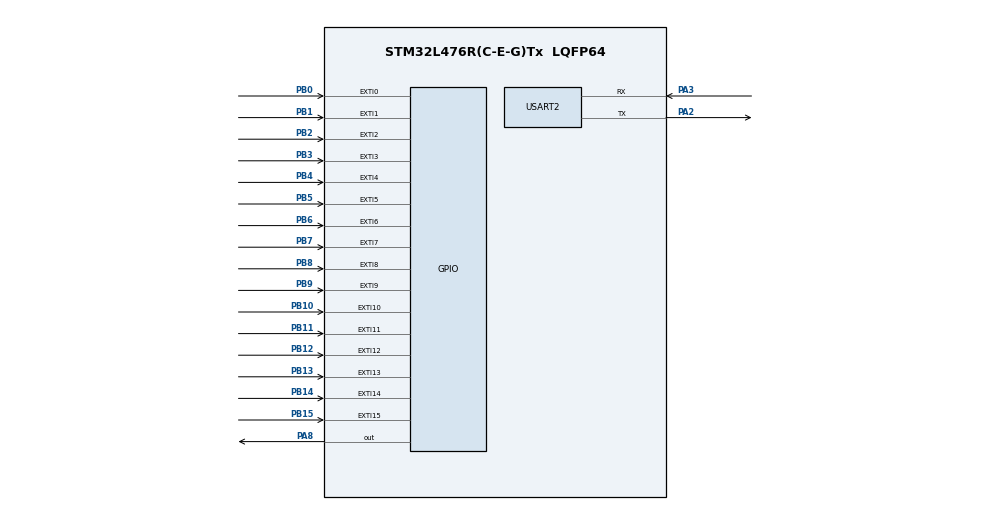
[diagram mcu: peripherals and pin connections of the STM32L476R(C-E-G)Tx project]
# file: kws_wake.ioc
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Dma.Request0=USART2_TX
Dma.USART2_TX.0.Direction=DMA_MEMORY_TO_PERIPH
Dma.USART2_TX.0.Instance=DMA1_Channel7
Dma.USART2_TX.0.MemDataAlignment=DMA_MDATAALIGN_BYTE
Dma.USART2_TX.0.MemInc=DMA_MINC_ENABLE
Dma.USART2_TX.0.Mode=DMA_NORMAL
Dma.USART2_TX.0.PeriphDataAlignment=DMA_PDATAALIGN_BYTE
Dma.USART2_TX.0.PeriphInc=DMA_PINC_DISABLE
Dma.USART2_TX.0.Priority=DMA_PRIORITY_LOW
Mcu.Family=STM32L4
Mcu.Name=STM32L476R(C-E-G)Tx
Mcu.Package=LQFP64
NVIC.DMA1_Channel7_IRQn=true\:0\:0\:false\:false\:true\:false\:true\:true
NVIC.LPTIM1_IRQn=true\:0\:0\:false\:false\:true\:true\:true\:true
NVIC.PriorityGroup=NVIC_PRIORITYGROUP_4
NVIC.USART2_IRQn=true\:0\:0\:false\:false\:true\:false\:true\:true
PA13\ (JTMS-SWDIO).Mode=Serial_Wire
PA13\ (JTMS-SWDIO).Signal=SYS_JTMS-SWDIO
PA14\ (JTCK-SWCLK).Mode=Serial_Wire
PA14\ (JTCK-SWCLK).Signal=SYS_JTCK-SWCLK
PA2.Mode=Asynchronous
PA2.Signal=USART2_TX
PA3.Mode=Asynchronous
PA3.Signal=USART2_RX
PA8.Signal=GPIO_Output
PB0.Signal=GPXTI0
PB1.Signal=GPXTI1
PB10.Signal=GPXTI10
PB11.Signal=GPXTI11
PB12.Signal=GPXTI12
PB13.Signal=GPXTI13
PB14.Signal=GPXTI14
PB15.Signal=GPXTI15
PB2.Signal=GPXTI2
PB3\ (JTDO-TRACESWO).Signal=GPXTI3
PB4\ (NJTRST).Signal=GPXTI4
PB5.Signal=GPXTI5
PB6.Signal=GPXTI6
PB7.Signal=GPXTI7
PB8.Signal=GPXTI8
PB9.Signal=GPXTI9
PC14-OSC32_IN\ (PC14).Mode=LSE-External-Oscillator
PC14-OSC32_IN\ (PC14).Signal=RCC_OSC32_IN
PC15-OSC32_OUT\ (PC15).Mode=LSE-External-Oscillator
PC15-OSC32_OUT\ (PC15).Signal=RCC_OSC32_OUT
ProjectManager.HeapSize=0x200
ProjectManager.StackSize=0x400
ProjectManager.TargetToolchain=STM32CubeIDE
RCC.HSE_VALUE=8000000
RCC.HSI_VALUE=16000000
RCC.LPTIM1CLockSelection=RCC_LPTIM1CLKSOURCE_LSE
RCC.MSI_VALUE=4000000
RCC.VCOOutputFreq_Value=32000000
USART2.VirtualMode-Asynchronous=VM_ASYNC
VP_LPTIM1_VS_LPTIM_counterModeInternalClock.Mode=Counts__internal_clock_event_00
board=custom

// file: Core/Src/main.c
/* USER CODE BEGIN Header */
/**
  ******************************************************************************
  * @file           : main.c
  * @brief          : Main program body
  ******************************************************************************
  * @attention
  *
  * Copyright (c) 2026 STMicroelectronics.
  * All rights reserved.
  *
  * This software is licensed under terms that can be found in the LICENSE file
  * in the root directory of this software component.
  * If no LICENSE file comes with this software, it is provided AS-IS.
  *
  ******************************************************************************
  */
/* USER CODE END Header */
#include "main.h"

/* USER CODE BEGIN Includes */
#include "board.h"

/* USER CODE END Includes */

LPTIM_HandleTypeDef hlptim1;

UART_HandleTypeDef huart2;
DMA_HandleTypeDef hdma_usart2_tx;

void SystemClock_Config(void);
static void MX_GPIO_Init(void);
static void MX_DMA_Init(void);
static void MX_USART2_UART_Init(void);
static void MX_LPTIM1_Init(void);

int main(void)
{

  /* MCU Configuration--------------------------------------------------------*/

  /* Reset of all peripherals, Initializes the Flash interface and the Systick. */
  HAL_Init();

  /* Configure the system clock */
  SystemClock_Config();

  /* Initialize all configured peripherals */
  MX_GPIO_Init();
  MX_DMA_Init();
  MX_USART2_UART_Init();
  MX_LPTIM1_Init();
  /* USER CODE BEGIN 2 */
  board_init();

  /* USER CODE END 2 */

  /* Infinite loop */
  while (1)
  {

    /* USER CODE BEGIN 3 */
    board_poll();
  }
  /* USER CODE END 3 */
}

void SystemClock_Config(void)
{
  RCC_OscInitTypeDef RCC_OscInitStruct = {0};
  RCC_ClkInitTypeDef RCC_ClkInitStruct = {0};

  /** Configure the main internal regulator output voltage
  */
  if (HAL_PWREx_ControlVoltageScaling(PWR_REGULATOR_VOLTAGE_SCALE1) != HAL_OK)
  {
    Error_Handler();
  }

  /** Configure LSE Drive Capability
  */
  HAL_PWR_EnableBkUpAccess();
  __HAL_RCC_LSEDRIVE_CONFIG(RCC_LSEDRIVE_LOW);

  /** Initializes the RCC Oscillators according to the specified parameters
  * in the RCC_OscInitTypeDef structure.
  */
  RCC_OscInitStruct.OscillatorType = RCC_OSCILLATORTYPE_LSE|RCC_OSCILLATORTYPE_MSI;
  RCC_OscInitStruct.LSEState = RCC_LSE_ON;
  RCC_OscInitStruct.MSIState = RCC_MSI_ON;
  RCC_OscInitStruct.MSICalibrationValue = 0;
  RCC_OscInitStruct.MSIClockRange = RCC_MSIRANGE_6;
  RCC_OscInitStruct.PLL.PLLState = RCC_PLL_NONE;
  if (HAL_RCC_OscConfig(&RCC_OscInitStruct) != HAL_OK)
  {
    Error_Handler();
  }

  /** Initializes the CPU, AHB and APB buses clocks
  */
  RCC_ClkInitStruct.ClockType = RCC_CLOCKTYPE_HCLK|RCC_CLOCKTYPE_SYSCLK
                              |RCC_CLOCKTYPE_PCLK1|RCC_CLOCKTYPE_PCLK2;
  RCC_ClkInitStruct.SYSCLKSource = RCC_SYSCLKSOURCE_MSI;
  RCC_ClkInitStruct.AHBCLKDivider = RCC_SYSCLK_DIV1;
  RCC_ClkInitStruct.APB1CLKDivider = RCC_HCLK_DIV1;
  RCC_ClkInitStruct.APB2CLKDivider = RCC_HCLK_DIV1;

  if (HAL_RCC_ClockConfig(&RCC_ClkInitStruct, FLASH_LATENCY_0) != HAL_OK)
  {
    Error_Handler();
  }

  /** Enable MSI Auto calibration
  */
  HAL_RCCEx_EnableMSIPLLMode();
}

static void MX_LPTIM1_Init(void)
{

  hlptim1.Instance = LPTIM1;
  hlptim1.Init.Clock.Source = LPTIM_CLOCKSOURCE_APBCLOCK_LPOSC;
  hlptim1.Init.Clock.Prescaler = LPTIM_PRESCALER_DIV1;
  hlptim1.Init.Trigger.Source = LPTIM_TRIGSOURCE_SOFTWARE;
  hlptim1.Init.OutputPolarity = LPTIM_OUTPUTPOLARITY_HIGH;
  hlptim1.Init.UpdateMode = LPTIM_UPDATE_IMMEDIATE;
  hlptim1.Init.CounterSource = LPTIM_COUNTERSOURCE_INTERNAL;
  hlptim1.Init.Input1Source = LPTIM_INPUT1SOURCE_GPIO;
  hlptim1.Init.Input2Source = LPTIM_INPUT2SOURCE_GPIO;
  if (HAL_LPTIM_Init(&hlptim1) != HAL_OK)
  {
    Error_Handler();
  }

}

static void MX_USART2_UART_Init(void)
{

  huart2.Instance = USART2;
  huart2.Init.BaudRate = 115200;
  huart2.Init.WordLength = UART_WORDLENGTH_8B;
  huart2.Init.StopBits = UART_STOPBITS_1;
  huart2.Init.Parity = UART_PARITY_NONE;
  huart2.Init.Mode = UART_MODE_TX_RX;
  huart2.Init.HwFlowCtl = UART_HWCONTROL_NONE;
  huart2.Init.OverSampling = UART_OVERSAMPLING_16;
  huart2.Init.OneBitSampling = UART_ONE_BIT_SAMPLE_DISABLE;
  huart2.AdvancedInit.AdvFeatureInit = UART_ADVFEATURE_NO_INIT;
  if (HAL_UART_Init(&huart2) != HAL_OK)
  {
    Error_Handler();
  }

}

static void MX_DMA_Init(void)
{

  /* DMA controller clock enable */
  __HAL_RCC_DMA1_CLK_ENABLE();

  /* DMA interrupt init */
  /* DMA1_Channel7_IRQn interrupt configuration */
  HAL_NVIC_SetPriority(DMA1_Channel7_IRQn, 0, 0);
  HAL_NVIC_EnableIRQ(DMA1_Channel7_IRQn);

}

static void MX_GPIO_Init(void)
{
  GPIO_InitTypeDef GPIO_InitStruct = {0};

  /* GPIO Ports Clock Enable */
  __HAL_RCC_GPIOC_CLK_ENABLE();
  __HAL_RCC_GPIOA_CLK_ENABLE();
  __HAL_RCC_GPIOB_CLK_ENABLE();

  /*Configure GPIO pin Output Level */
  HAL_GPIO_WritePin(GPIOA, GPIO_PIN_8, GPIO_PIN_RESET);

  /*Configure GPIO pins : PB0 PB1 PB2 PB10
                           PB11 PB12 PB13 PB14
                           PB15 PB3 PB4 PB5
                           PB6 PB7 PB8 PB9 */
  GPIO_InitStruct.Pin = GPIO_PIN_0|GPIO_PIN_1|GPIO_PIN_2|GPIO_PIN_10
                          |GPIO_PIN_11|GPIO_PIN_12|GPIO_PIN_13|GPIO_PIN_14
                          |GPIO_PIN_15|GPIO_PIN_3|GPIO_PIN_4|GPIO_PIN_5
                          |GPIO_PIN_6|GPIO_PIN_7|GPIO_PIN_8|GPIO_PIN_9;
  GPIO_InitStruct.Mode = GPIO_MODE_IT_RISING;
  GPIO_InitStruct.Pull = GPIO_NOPULL;
  HAL_GPIO_Init(GPIOB, &GPIO_InitStruct);

  /*Configure GPIO pin : PA8 */
  GPIO_InitStruct.Pin = GPIO_PIN_8;
  GPIO_InitStruct.Mode = GPIO_MODE_OUTPUT_PP;
  GPIO_InitStruct.Pull = GPIO_NOPULL;
  GPIO_InitStruct.Speed = GPIO_SPEED_FREQ_LOW;
  HAL_GPIO_Init(GPIOA, &GPIO_InitStruct);

}

void Error_Handler(void)
{
  __disable_irq();
  while (1)
  {
  }
}
